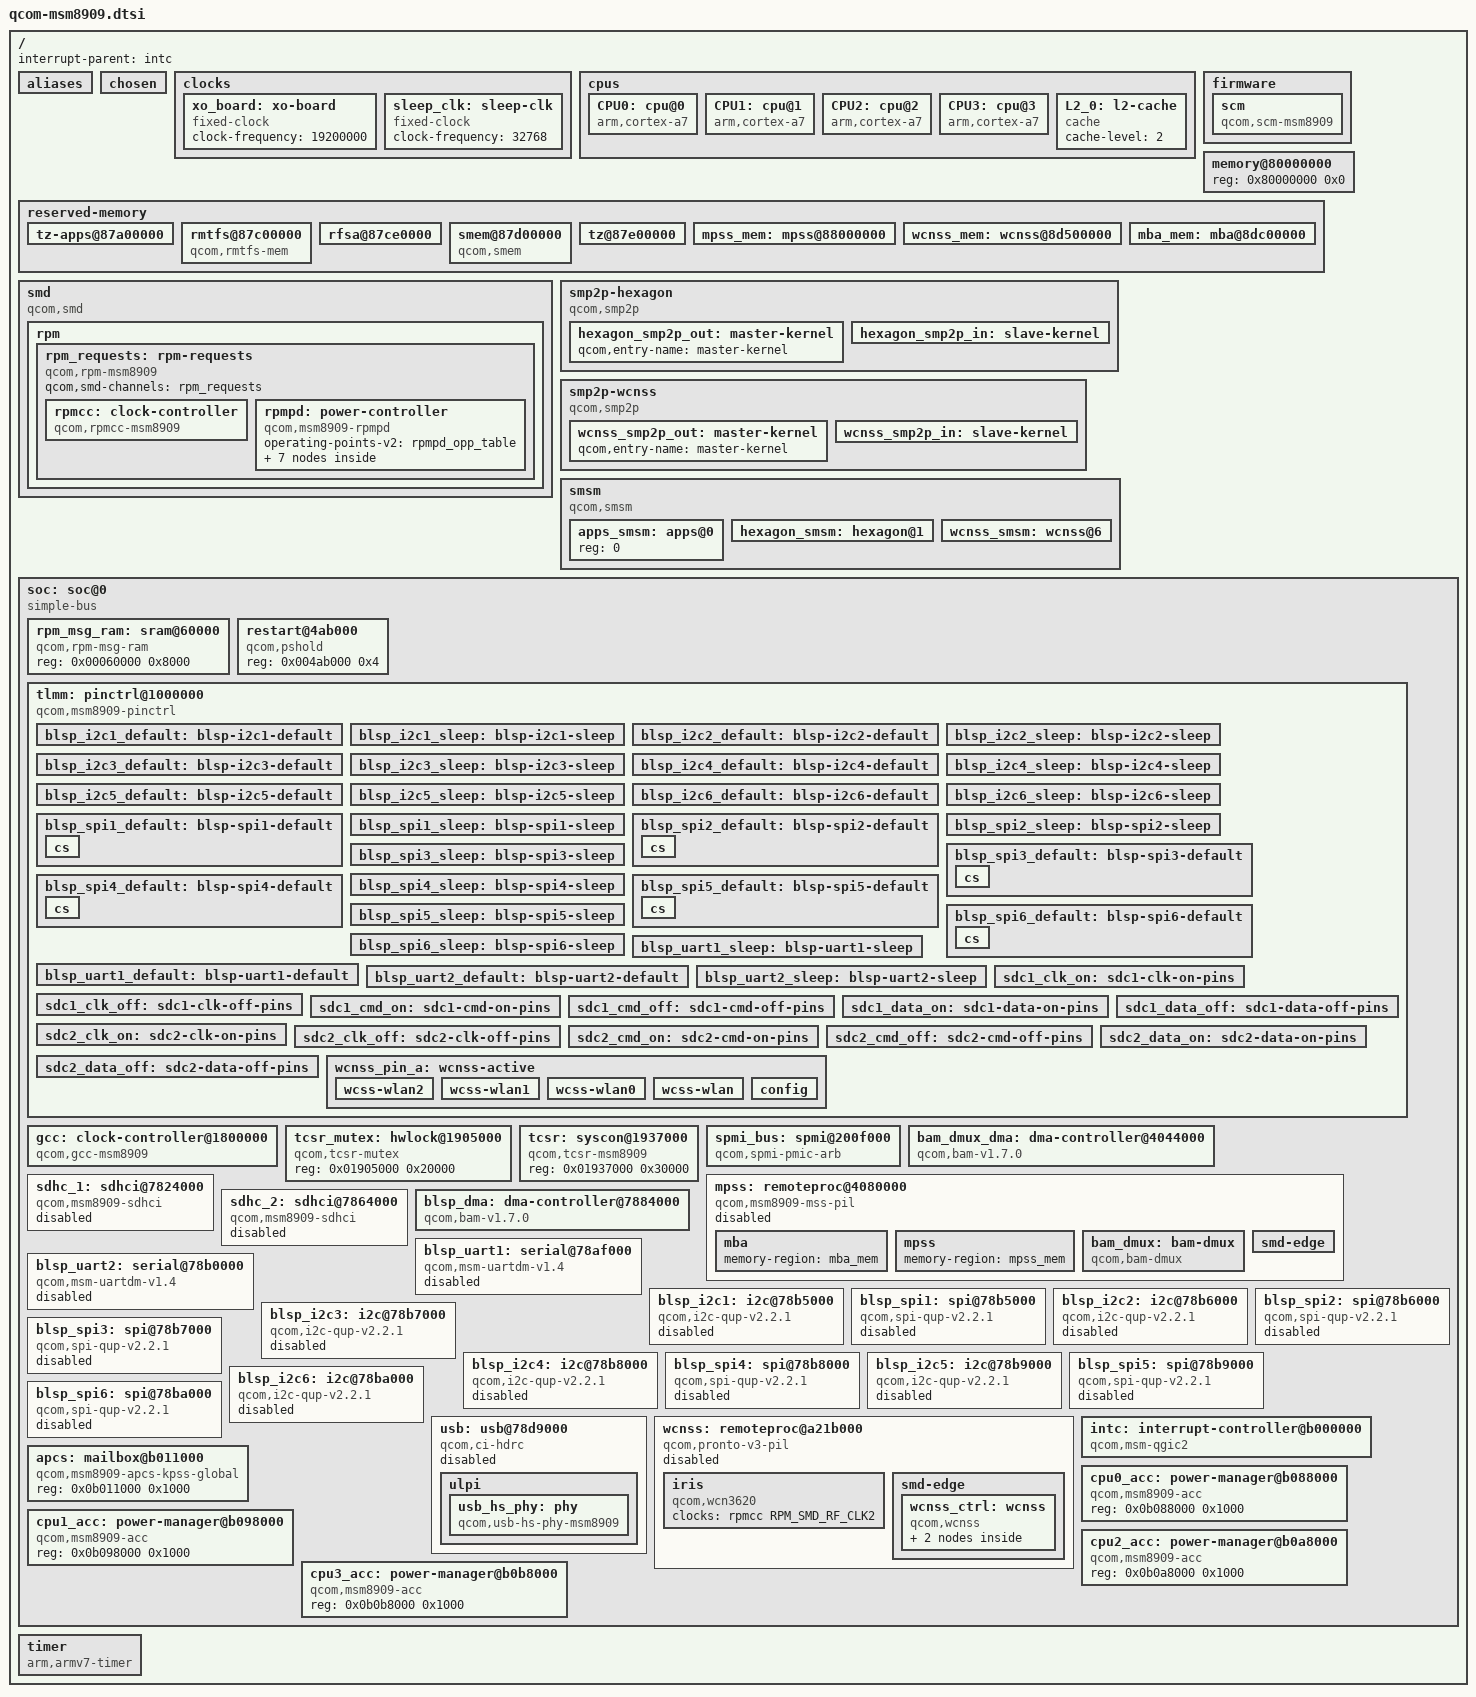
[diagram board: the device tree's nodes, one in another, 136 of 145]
// SPDX-License-Identifier: GPL-2.0-only
/*
 * Copyright (c) 2014-2019, The Linux Foundation. All rights reserved.
 */
/dts-v1/;

#include <dt-bindings/clock/qcom,gcc-msm8909.h>
#include <dt-bindings/clock/qcom,rpmcc.h>
#include <dt-bindings/gpio/gpio.h>
#include <dt-bindings/interrupt-controller/arm-gic.h>
#include <dt-bindings/power/qcom-rpmpd.h>
#include <dt-bindings/reset/qcom,gcc-msm8909.h>

/ {
	#address-cells = <1>;
	#size-cells = <1>;
	interrupt-parent = <&intc>;

	aliases {
		mmc0 = &sdhc_1; /* SDC1 eMMC slot */
		mmc1 = &sdhc_2; /* SDC2 SD card slot */
	};

	chosen { };

	clocks {
		xo_board: xo-board {
			compatible = "fixed-clock";
			#clock-cells = <0>;
			clock-frequency = <19200000>;
		};

		sleep_clk: sleep-clk {
			compatible = "fixed-clock";
			#clock-cells = <0>;
			clock-frequency = <32768>;
		};
	};

	cpus {
		#address-cells = <1>;
		#size-cells = <0>;

		CPU0: cpu@0 {
			device_type = "cpu";
			compatible = "arm,cortex-a7";
			reg = <0x0>;
			next-level-cache = <&L2_0>;
			enable-method = "qcom,msm8909-smp";
			qcom,acc = <&cpu0_acc>;
		};

		CPU1: cpu@1 {
			device_type = "cpu";
			compatible = "arm,cortex-a7";
			reg = <0x1>;
			next-level-cache = <&L2_0>;
			enable-method = "qcom,msm8909-smp";
			qcom,acc = <&cpu1_acc>;
		};

		CPU2: cpu@2 {
			device_type = "cpu";
			compatible = "arm,cortex-a7";
			reg = <0x2>;
			next-level-cache = <&L2_0>;
			enable-method = "qcom,msm8909-smp";
			qcom,acc = <&cpu2_acc>;
		};

		CPU3: cpu@3 {
			device_type = "cpu";
			compatible = "arm,cortex-a7";
			reg = <0x3>;
			next-level-cache = <&L2_0>;
			enable-method = "qcom,msm8909-smp";
			qcom,acc = <&cpu3_acc>;
		};

		L2_0: l2-cache {
			compatible = "cache";
			cache-level = <2>;
		};
	};

	firmware {
		scm: scm {
			compatible = "qcom,scm-msm8909", "qcom,scm";
			clocks = <&gcc GCC_CRYPTO_CLK>,
				 <&gcc GCC_CRYPTO_AXI_CLK>,
				 <&gcc GCC_CRYPTO_AHB_CLK>;
			clock-names = "core", "bus", "iface";
		};
	};

	memory@80000000 {
		device_type = "memory";
		/* We expect the bootloader to fill in the reg */
		reg = <0x80000000 0x0>;
	};

	reserved-memory {
		#address-cells = <1>;
		#size-cells = <1>;
		ranges;

		tz-apps@87a00000 {
			reg = <0x87a00000 0x200000>;
			no-map;
		};
		rmtfs@87c00000 {
			compatible = "qcom,rmtfs-mem";
			reg = <0x87c00000 0xe0000>;
			no-map;

			qcom,client-id = <1>;
		};
		rfsa@87ce0000 {
			reg = <0x87ce0000 0x20000>;
			no-map;
		};
		smem@87d00000 {
			compatible = "qcom,smem";
			reg = <0x87d00000 0x100000>;
			no-map;

			hwlocks = <&tcsr_mutex 3>;
			qcom,rpm-msg-ram = <&rpm_msg_ram>;
		};
		tz@87e00000 {
			reg = <0x87e00000 0x200000>;
			no-map;
		};

		mpss_mem: mpss@88000000 {
			reg = <0x88000000 0x05500000>;
			no-map;
		};
		wcnss_mem: wcnss@8d500000 {
			reg = <0x8d500000 0x700000>;
			no-map;
		};
		mba_mem: mba@8dc00000 {
			reg = <0x8dc00000 0x100000>;
			no-map;
		};
	};

	smd {
		compatible = "qcom,smd";

		rpm {
			interrupts = <GIC_SPI 168 IRQ_TYPE_EDGE_RISING>;
			qcom,ipc = <&apcs 8 0>;
			qcom,smd-edge = <15>;

			rpm_requests: rpm-requests {
				compatible = "qcom,rpm-msm8909";
				qcom,smd-channels = "rpm_requests";

				rpmcc: clock-controller {
					compatible = "qcom,rpmcc-msm8909";
					#clock-cells = <1>;
				};

				rpmpd: power-controller {
					compatible = "qcom,msm8909-rpmpd";
					#power-domain-cells = <1>;
					operating-points-v2 = <&rpmpd_opp_table>;

					rpmpd_opp_table: opp-table {
						compatible = "operating-points-v2";

						rpmpd_opp_ret: opp1 {
							opp-level = <1>;
						};
						rpmpd_opp_svs_krait: opp2 {
							opp-level = <2>;
						};
						rpmpd_opp_svs_soc: opp3 {
							opp-level = <3>;
						};
						rpmpd_opp_nom: opp4 {
							opp-level = <4>;
						};
						rpmpd_opp_turbo: opp5 {
							opp-level = <5>;
						};
						rpmpd_opp_super_turbo: opp6 {
							opp-level = <6>;
						};
					};
				};
			};
		};
	};

	smp2p-hexagon {
		compatible = "qcom,smp2p";
		qcom,smem = <435>, <428>;

		interrupts = <GIC_SPI 27 IRQ_TYPE_EDGE_RISING>;

		qcom,ipc = <&apcs 8 14>;

		qcom,local-pid = <0>;
		qcom,remote-pid = <1>;

		hexagon_smp2p_out: master-kernel {
			qcom,entry-name = "master-kernel";

			#qcom,smem-state-cells = <1>;
		};

		hexagon_smp2p_in: slave-kernel {
			qcom,entry-name = "slave-kernel";

			interrupt-controller;
			#interrupt-cells = <2>;
		};
	};

	smp2p-wcnss {
		compatible = "qcom,smp2p";
		qcom,smem = <451>, <431>;

		interrupts = <GIC_SPI 143 IRQ_TYPE_EDGE_RISING>;

		qcom,ipc = <&apcs 8 18>;

		qcom,local-pid = <0>;
		qcom,remote-pid = <4>;

		wcnss_smp2p_out: master-kernel {
			qcom,entry-name = "master-kernel";

			#qcom,smem-state-cells = <1>;
		};

		wcnss_smp2p_in: slave-kernel {
			qcom,entry-name = "slave-kernel";

			interrupt-controller;
			#interrupt-cells = <2>;
		};
	};

	smsm {
		compatible = "qcom,smsm";

		#address-cells = <1>;
		#size-cells = <0>;

		qcom,ipc-1 = <&apcs 8 13>;
		qcom,ipc-3 = <&apcs 8 19>;

		apps_smsm: apps@0 {
			reg = <0>;

			#qcom,smem-state-cells = <1>;
		};

		hexagon_smsm: hexagon@1 {
			reg = <1>;
			interrupts = <GIC_SPI 26 IRQ_TYPE_EDGE_RISING>;

			interrupt-controller;
			#interrupt-cells = <2>;
		};

		wcnss_smsm: wcnss@6 {
			reg = <6>;
			interrupts = <GIC_SPI 144 IRQ_TYPE_EDGE_RISING>;

			interrupt-controller;
			#interrupt-cells = <2>;
		};
	};

	soc: soc@0 {
		compatible = "simple-bus";
		#address-cells = <1>;
		#size-cells = <1>;
		ranges;

		rpm_msg_ram: sram@60000 {
			compatible = "qcom,rpm-msg-ram";
			reg = <0x00060000 0x8000>;
		};

		restart@4ab000 {
			compatible = "qcom,pshold";
			reg = <0x004ab000 0x4>;
		};

		tlmm: pinctrl@1000000 {
			compatible = "qcom,msm8909-pinctrl";
			reg = <0x01000000 0x300000>;
			interrupts = <GIC_SPI 208 IRQ_TYPE_LEVEL_HIGH>;
			gpio-controller;
			#gpio-cells = <2>;
			gpio-ranges = <&tlmm 0 0 117>;
			interrupt-controller;
			#interrupt-cells = <2>;

			blsp_i2c1_default: blsp-i2c1-default {
				pins = "gpio6", "gpio7";
				function = "blsp_i2c1";

				drive-strength = <2>;
				bias-disable;
			};

			blsp_i2c1_sleep: blsp-i2c1-sleep {
				pins = "gpio6", "gpio7";
				function = "gpio";

				drive-strength = <2>;
				bias-disable;
			};

			blsp_i2c2_default: blsp-i2c2-default {
				pins = "gpio111", "gpio112";
				function = "blsp_i2c2";

				drive-strength = <2>;
				bias-disable;
			};

			blsp_i2c2_sleep: blsp-i2c2-sleep {
				pins = "gpio111", "gpio112";
				function = "gpio";

				drive-strength = <2>;
				bias-disable;
			};

			blsp_i2c3_default: blsp-i2c3-default {
				pins = "gpio29", "gpio30";
				function = "blsp_i2c3";

				drive-strength = <2>;
				bias-disable;
			};

			blsp_i2c3_sleep: blsp-i2c3-sleep {
				pins = "gpio29", "gpio30";
				function = "gpio";

				drive-strength = <2>;
				bias-disable;
			};

			blsp_i2c4_default: blsp-i2c4-default {
				pins = "gpio14", "gpio15";
				function = "blsp_i2c4";

				drive-strength = <2>;
				bias-disable;
			};

			blsp_i2c4_sleep: blsp-i2c4-sleep {
				pins = "gpio14", "gpio15";
				function = "gpio";

				drive-strength = <2>;
				bias-disable;
			};

			blsp_i2c5_default: blsp-i2c5-default {
				pins = "gpio18", "gpio19";
				function = "blsp_i2c5";

				drive-strength = <2>;
				bias-disable;
			};

			blsp_i2c5_sleep: blsp-i2c5-sleep {
				pins = "gpio18", "gpio19";
				function = "gpio";

				drive-strength = <2>;
				bias-disable;
			};

			blsp_i2c6_default: blsp-i2c6-default {
				pins = "gpio10", "gpio11";
				function = "blsp_i2c6";

				drive-strength = <2>;
				bias-disable;
			};

			blsp_i2c6_sleep: blsp-i2c6-sleep {
				pins = "gpio10", "gpio11";
				function = "gpio";

				drive-strength = <2>;
				bias-disable;
			};

			blsp_spi1_default: blsp-spi1-default {
				pins = "gpio4", "gpio5", "gpio7";
				function = "blsp_spi1";

				drive-strength = <12>;
				bias-disable;

				cs {
					pins = "gpio6";
					function = "gpio";

					drive-strength = <2>;
					bias-disable;
					output-high;
				};
			};

			blsp_spi1_sleep: blsp-spi1-sleep {
				pins = "gpio4", "gpio5", "gpio6", "gpio7";
				function = "gpio";

				drive-strength = <2>;
				bias-pull-down;
			};

			blsp_spi2_default: blsp-spi2-default {
				pins = "gpio20", "gpio21", "gpio112";
				function = "blsp_spi2";

				drive-strength = <12>;
				bias-disable;

				cs {
					pins = "gpio111";
					function = "gpio";

					drive-strength = <2>;
					bias-disable;
					output-high;
				};
			};

			blsp_spi2_sleep: blsp-spi2-sleep {
				pins = "gpio20", "gpio21", "gpio111", "gpio112";
				function = "gpio";

				drive-strength = <2>;
				bias-pull-down;
			};

			blsp_spi3_default: blsp-spi3-default {
				pins = "gpio0", "gpio1", "gpio3";
				function = "blsp_spi3";

				drive-strength = <12>;
				bias-disable;

				cs {
					pins = "gpio2";
					function = "gpio";

					drive-strength = <2>;
					bias-disable;
					output-high;
				};
			};

			blsp_spi3_sleep: blsp-spi3-sleep {
				pins = "gpio0", "gpio1", "gpio2", "gpio3";
				function = "gpio";

				drive-strength = <2>;
				bias-pull-down;
			};

			blsp_spi4_default: blsp-spi4-default {
				pins = "gpio12", "gpio13", "gpio15";
				function = "blsp_spi4";

				drive-strength = <12>;
				bias-disable;

				cs {
					pins = "gpio14";
					function = "gpio";

					drive-strength = <2>;
					bias-disable;
					output-high;
				};
			};

			blsp_spi4_sleep: blsp-spi4-sleep {
				pins = "gpio12", "gpio13", "gpio14", "gpio15";
				function = "gpio";

				drive-strength = <2>;
				bias-pull-down;
			};

			blsp_spi5_default: blsp-spi5-default {
				pins = "gpio16", "gpio17", "gpio19";
				function = "blsp_spi5";

				drive-strength = <12>;
				bias-disable;

				cs {
					pins = "gpio18";
					function = "gpio";

					drive-strength = <2>;
					bias-disable;
					output-high;
				};
			};

			blsp_spi5_sleep: blsp-spi5-sleep {
				pins = "gpio16", "gpio17", "gpio18", "gpio19";
				function = "gpio";

				drive-strength = <2>;
				bias-pull-down;
			};

			blsp_spi6_default: blsp-spi6-default {
				pins = "gpio8", "gpio9", "gpio11";
				function = "blsp_spi6";

				drive-strength = <12>;
				bias-disable;

				cs {
					pins = "gpio10";
					function = "gpio";

					drive-strength = <2>;
					bias-pull-up;
				};
			};

			blsp_spi6_sleep: blsp-spi6-sleep {
				pins = "gpio8", "gpio9", "gpio10", "gpio11";
				function = "gpio";

				drive-strength = <2>;
				bias-pull-down;
			};

			blsp_uart1_default: blsp-uart1-default {
				pins = "gpio4", "gpio5";
				function = "blsp_uart1";

				drive-strength = <2>;
				bias-disable;
			};

			blsp_uart1_sleep: blsp-uart1-sleep {
				pins = "gpio4", "gpio5";
				function = "gpio";

				drive-strength = <2>;
				bias-pull-down;
			};

			blsp_uart2_default: blsp-uart2-default {
				pins = "gpio20", "gpio21";
				function = "blsp_uart2";

				drive-strength = <2>;
				bias-disable;
			};

			blsp_uart2_sleep: blsp-uart2-sleep {
				pins = "gpio20", "gpio21";
				function = "gpio";

				drive-strength = <2>;
				bias-pull-down;
			};

			sdc1_clk_on: sdc1-clk-on-pins {
				pins = "sdc1_clk";
				bias-disable;
				drive-strength = <16>;
			};

			sdc1_clk_off: sdc1-clk-off-pins {
				pins = "sdc1_clk";
				bias-disable;
				drive-strength = <2>;
			};

			sdc1_cmd_on: sdc1-cmd-on-pins {
				pins = "sdc1_cmd";
				bias-disable;
				drive-strength = <10>;
			};

			sdc1_cmd_off: sdc1-cmd-off-pins {
				pins = "sdc1_cmd";
				bias-disable;
				drive-strength = <2>;
			};

			sdc1_data_on: sdc1-data-on-pins {
				pins = "sdc1_data";
				bias-pull-up;
				drive-strength = <10>;
			};

			sdc1_data_off: sdc1-data-off-pins {
				pins = "sdc1_data";
				bias-pull-up;
				drive-strength = <2>;
			};

			sdc2_clk_on: sdc2-clk-on-pins {
				pins = "sdc2_clk";
				drive-strength = <16>;
				bias-disable;
			};

			sdc2_clk_off: sdc2-clk-off-pins {
				pins = "sdc2_clk";
				bias-disable;
				drive-strength = <2>;
			};

			sdc2_cmd_on: sdc2-cmd-on-pins {
				pins = "sdc2_cmd";
				bias-pull-up;
				drive-strength = <10>;
			};

			sdc2_cmd_off: sdc2-cmd-off-pins {
				pins = "sdc2_cmd";
				bias-pull-up;
				drive-strength = <2>;
			};

			sdc2_data_on: sdc2-data-on-pins {
				pins = "sdc2_data";
				bias-pull-up;
				drive-strength = <10>;
			};

			sdc2_data_off: sdc2-data-off-pins {
				pins = "sdc2_data";
				bias-pull-up;
				drive-strength = <2>;
			};

			wcnss_pin_a: wcnss-active {
				wcss-wlan2 {
					pins = "gpio40";
					function = "wcss_wlan2";
				};
				wcss-wlan1 {
					pins = "gpio41";
					function = "wcss_wlan1";
				};
				wcss-wlan0 {
					pins = "gpio42";
					function = "wcss_wlan0";
				};
				wcss-wlan {
					pins = "gpio43", "gpio44";
					function = "wcss_wlan";
				};
				config {
					pins = "gpio40", "gpio41", "gpio42",
					       "gpio43", "gpio44";
					drive-strength = <6>;
					bias-pull-up;
				};
			};
		};

		gcc: clock-controller@1800000 {
			compatible = "qcom,gcc-msm8909";
			reg = <0x01800000 0x80000>;
			#clock-cells = <1>;
			#reset-cells = <1>;
			#power-domain-cells = <1>;
			clocks = <&xo_board>, <&sleep_clk>;
			clock-names = "xo", "sleep_clk";
		};

		tcsr_mutex: hwlock@1905000 {
			compatible = "qcom,tcsr-mutex";
			reg = <0x01905000 0x20000>;
			#hwlock-cells = <1>;
		};

		tcsr: syscon@1937000 {
			compatible = "qcom,tcsr-msm8909", "syscon";
			reg = <0x01937000 0x30000>;
		};

		spmi_bus: spmi@200f000 {
			compatible = "qcom,spmi-pmic-arb";
			reg = <0x0200f000 0x001000>,
			      <0x02400000 0x400000>,
			      <0x02c00000 0x400000>,
			      <0x03800000 0x200000>,
			      <0x0200a000 0x002100>;
			reg-names = "core", "chnls", "obsrvr", "intr", "cnfg";
			interrupt-names = "periph_irq";
			interrupts = <GIC_SPI 190 IRQ_TYPE_LEVEL_HIGH>;
			qcom,ee = <0>;
			qcom,channel = <0>;
			#address-cells = <2>;
			#size-cells = <0>;
			interrupt-controller;
			#interrupt-cells = <4>;
		};

		bam_dmux_dma: dma-controller@4044000 {
			compatible = "qcom,bam-v1.7.0";
			reg = <0x04044000 0x19000>;
			interrupts = <GIC_SPI 29 IRQ_TYPE_LEVEL_HIGH>;
			#dma-cells = <1>;
			qcom,ee = <0>;

			num-channels = <6>;
			qcom,num-ees = <1>;
			qcom,powered-remotely;
		};

		mpss: remoteproc@4080000 {
			compatible = "qcom,msm8909-mss-pil";
			reg = <0x04080000 0x100>,
			      <0x04020000 0x040>;
			reg-names = "qdsp6", "rmb";

			interrupts-extended = <&intc GIC_SPI 24 IRQ_TYPE_EDGE_RISING>,
					      <&hexagon_smp2p_in 0 IRQ_TYPE_EDGE_RISING>,
					      <&hexagon_smp2p_in 1 IRQ_TYPE_EDGE_RISING>,
					      <&hexagon_smp2p_in 2 IRQ_TYPE_EDGE_RISING>,
					      <&hexagon_smp2p_in 3 IRQ_TYPE_EDGE_RISING>;
			interrupt-names = "wdog", "fatal", "ready",
					  "handover", "stop-ack";

			power-domains = <&rpmpd MSM8909_VDDCX>,
					<&rpmpd MSM8909_VDDMX_AO>;
			power-domain-names = "cx", "mx";

			clocks = <&gcc GCC_MSS_CFG_AHB_CLK>,
				 <&gcc GCC_MSS_Q6_BIMC_AXI_CLK>,
				 <&gcc GCC_BOOT_ROM_AHB_CLK>,
				 <&xo_board>;
			clock-names = "iface", "bus", "mem", "xo";

			qcom,smem-states = <&hexagon_smp2p_out 0>;
			qcom,smem-state-names = "stop";

			resets = <&gcc GCC_MSS_RESTART>;
			reset-names = "mss_restart";

			qcom,halt-regs = <&tcsr 0x18000 0x19000 0x1a000>;

			status = "disabled";

			mba {
				memory-region = <&mba_mem>;
			};

			mpss {
				memory-region = <&mpss_mem>;
			};

			bam_dmux: bam-dmux {
				compatible = "qcom,bam-dmux";

				interrupt-parent = <&hexagon_smsm>;
				interrupts = <1 IRQ_TYPE_EDGE_BOTH>, <11 IRQ_TYPE_EDGE_BOTH>;
				interrupt-names = "pc", "pc-ack";

				qcom,smem-states = <&apps_smsm 1>, <&apps_smsm 11>;
				qcom,smem-state-names = "pc", "pc-ack";

				dmas = <&bam_dmux_dma 4>, <&bam_dmux_dma 5>;
				dma-names = "tx", "rx";
			};

			smd-edge {
				interrupts = <GIC_SPI 25 IRQ_TYPE_EDGE_RISING>;

				qcom,smd-edge = <0>;
				qcom,ipc = <&apcs 8 12>;
				qcom,remote-pid = <1>;

				label = "hexagon";
			};
		};

		sdhc_1: sdhci@7824000 {
			compatible = "qcom,msm8909-sdhci", "qcom,sdhci-msm-v4";
			reg = <0x07824900 0x11c>, <0x07824000 0x800>;
			reg-names = "hc_mem", "core_mem";

			interrupts = <GIC_SPI 123 IRQ_TYPE_LEVEL_HIGH>,
				     <GIC_SPI 138 IRQ_TYPE_LEVEL_HIGH>;
			interrupt-names = "hc_irq", "pwr_irq";
			clocks = <&gcc GCC_SDCC1_APPS_CLK>,
				 <&gcc GCC_SDCC1_AHB_CLK>,
				 <&xo_board>;
			clock-names = "core", "iface", "xo";

			pinctrl-names = "default", "sleep";
			pinctrl-0 = <&sdc1_clk_on &sdc1_cmd_on &sdc1_data_on>;
			pinctrl-1 = <&sdc1_clk_off &sdc1_cmd_off &sdc1_data_off>;

			mmc-hs200-1_8v;
			mmc-ddr-1_8v;
			bus-width = <8>;
			non-removable;
			status = "disabled";
		};

		sdhc_2: sdhci@7864000 {
			compatible = "qcom,msm8909-sdhci", "qcom,sdhci-msm-v4";
			reg = <0x07864900 0x11c>, <0x07864000 0x800>;
			reg-names = "hc_mem", "core_mem";

			interrupts = <GIC_SPI 125 IRQ_TYPE_LEVEL_HIGH>,
				     <GIC_SPI 221 IRQ_TYPE_LEVEL_HIGH>;
			interrupt-names = "hc_irq", "pwr_irq";
			clocks = <&gcc GCC_SDCC2_APPS_CLK>,
				 <&gcc GCC_SDCC2_AHB_CLK>,
				 <&xo_board>;
			clock-names = "core", "iface", "xo";

			pinctrl-names = "default", "sleep";
			pinctrl-0 = <&sdc2_clk_on &sdc2_cmd_on &sdc2_data_on>;
			pinctrl-1 = <&sdc2_clk_off &sdc2_cmd_off &sdc2_data_off>;

			bus-width = <4>;
			status = "disabled";
		};

		blsp_dma: dma-controller@7884000 {
			compatible = "qcom,bam-v1.7.0";
			reg = <0x07884000 0x23000>;
			interrupts = <GIC_SPI 238 IRQ_TYPE_LEVEL_HIGH>;
			clocks = <&gcc GCC_BLSP1_AHB_CLK>;
			clock-names = "bam_clk";
			#dma-cells = <1>;
			qcom,ee = <0>;
		};

		blsp_uart1: serial@78af000 {
			compatible = "qcom,msm-uartdm-v1.4", "qcom,msm-uartdm";
			reg = <0x078af000 0x200>;
			interrupts = <GIC_SPI 107 IRQ_TYPE_LEVEL_HIGH>;
			clocks = <&gcc GCC_BLSP1_UART1_APPS_CLK>,
				 <&gcc GCC_BLSP1_AHB_CLK>;
			clock-names = "core", "iface";
			dmas = <&blsp_dma 0>, <&blsp_dma 1>;
			dma-names = "tx", "rx";
			pinctrl-names = "default", "sleep";
			pinctrl-0 = <&blsp_uart1_default>;
			pinctrl-1 = <&blsp_uart1_sleep>;
			status = "disabled";
		};

		blsp_uart2: serial@78b0000 {
			compatible = "qcom,msm-uartdm-v1.4", "qcom,msm-uartdm";
			reg = <0x078b0000 0x200>;
			interrupts = <GIC_SPI 108 IRQ_TYPE_LEVEL_HIGH>;
			clocks = <&gcc GCC_BLSP1_UART2_APPS_CLK>,
				 <&gcc GCC_BLSP1_AHB_CLK>;
			clock-names = "core", "iface";
			dmas = <&blsp_dma 2>, <&blsp_dma 3>;
			dma-names = "tx", "rx";
			pinctrl-names = "default", "sleep";
			pinctrl-0 = <&blsp_uart2_default>;
			pinctrl-1 = <&blsp_uart2_sleep>;
			status = "disabled";
		};

		blsp_i2c1: i2c@78b5000 {
			compatible = "qcom,i2c-qup-v2.2.1";
			reg = <0x078b5000 0x500>;
			interrupts = <GIC_SPI 95 IRQ_TYPE_LEVEL_HIGH>;
			clocks = <&gcc GCC_BLSP1_QUP1_I2C_APPS_CLK>,
				 <&gcc GCC_BLSP1_AHB_CLK>;
			clock-names = "core", "iface";
			pinctrl-names = "default", "sleep";
			pinctrl-0 = <&blsp_i2c1_default>;
			pinctrl-1 = <&blsp_i2c1_sleep>;
			#address-cells = <1>;
			#size-cells = <0>;
			status = "disabled";
		};

		blsp_spi1: spi@78b5000 {
			compatible = "qcom,spi-qup-v2.2.1";
			reg = <0x078b5000 0x500>;
			interrupts = <GIC_SPI 95 IRQ_TYPE_LEVEL_HIGH>;
			clocks = <&gcc GCC_BLSP1_QUP1_SPI_APPS_CLK>,
				 <&gcc GCC_BLSP1_AHB_CLK>;
			clock-names = "core", "iface";
			dmas = <&blsp_dma 4>, <&blsp_dma 5>;
			dma-names = "tx", "rx";
			pinctrl-names = "default", "sleep";
			pinctrl-0 = <&blsp_spi1_default>;
			pinctrl-1 = <&blsp_spi1_sleep>;
			#address-cells = <1>;
			#size-cells = <0>;
			status = "disabled";
		};

		blsp_i2c2: i2c@78b6000 {
			compatible = "qcom,i2c-qup-v2.2.1";
			reg = <0x078b6000 0x500>;
			interrupts = <GIC_SPI 96 IRQ_TYPE_LEVEL_HIGH>;
			clocks = <&gcc GCC_BLSP1_QUP2_I2C_APPS_CLK>,
				 <&gcc GCC_BLSP1_AHB_CLK>;
			clock-names = "core", "iface";
			pinctrl-names = "default", "sleep";
			pinctrl-0 = <&blsp_i2c2_default>;
			pinctrl-1 = <&blsp_i2c2_sleep>;
			#address-cells = <1>;
			#size-cells = <0>;
			status = "disabled";
		};

		blsp_spi2: spi@78b6000 {
			compatible = "qcom,spi-qup-v2.2.1";
			reg = <0x078b6000 0x500>;
			interrupts = <GIC_SPI 96 IRQ_TYPE_LEVEL_HIGH>;
			clocks = <&gcc GCC_BLSP1_QUP2_SPI_APPS_CLK>,
				 <&gcc GCC_BLSP1_AHB_CLK>;
			clock-names = "core", "iface";
			dmas = <&blsp_dma 6>, <&blsp_dma 7>;
			dma-names = "tx", "rx";
			pinctrl-names = "default", "sleep";
			pinctrl-0 = <&blsp_spi2_default>;
			pinctrl-1 = <&blsp_spi2_sleep>;
			#address-cells = <1>;
			#size-cells = <0>;
			status = "disabled";
		};

		blsp_i2c3: i2c@78b7000 {
			compatible = "qcom,i2c-qup-v2.2.1";
			reg = <0x078b7000 0x500>;
			interrupts = <GIC_SPI 97 IRQ_TYPE_LEVEL_HIGH>;
			clocks = <&gcc GCC_BLSP1_QUP3_I2C_APPS_CLK>,
				 <&gcc GCC_BLSP1_AHB_CLK>;
			clock-names = "core", "iface";
			pinctrl-names = "default", "sleep";
			pinctrl-0 = <&blsp_i2c3_default>;
			pinctrl-1 = <&blsp_i2c3_sleep>;
			#address-cells = <1>;
			#size-cells = <0>;
			status = "disabled";
		};

		blsp_spi3: spi@78b7000 {
			compatible = "qcom,spi-qup-v2.2.1";
			reg = <0x078b7000 0x500>;
			interrupts = <GIC_SPI 97 IRQ_TYPE_LEVEL_HIGH>;
			clocks = <&gcc GCC_BLSP1_QUP3_SPI_APPS_CLK>,
				 <&gcc GCC_BLSP1_AHB_CLK>;
			clock-names = "core", "iface";
			dmas = <&blsp_dma 8>, <&blsp_dma 9>;
			dma-names = "tx", "rx";
			pinctrl-names = "default", "sleep";
			pinctrl-0 = <&blsp_spi3_default>;
			pinctrl-1 = <&blsp_spi3_sleep>;
			#address-cells = <1>;
			#size-cells = <0>;
			status = "disabled";
		};

		blsp_i2c4: i2c@78b8000 {
			compatible = "qcom,i2c-qup-v2.2.1";
			reg = <0x078b8000 0x500>;
			interrupts = <GIC_SPI 98 IRQ_TYPE_LEVEL_HIGH>;
			clocks = <&gcc GCC_BLSP1_QUP4_I2C_APPS_CLK>,
				 <&gcc GCC_BLSP1_AHB_CLK>;
			clock-names = "core", "iface";
			pinctrl-names = "default", "sleep";
			pinctrl-0 = <&blsp_i2c4_default>;
			pinctrl-1 = <&blsp_i2c4_sleep>;
			#address-cells = <1>;
			#size-cells = <0>;
			status = "disabled";
		};

		blsp_spi4: spi@78b8000 {
			compatible = "qcom,spi-qup-v2.2.1";
			reg = <0x078b8000 0x500>;
			interrupts = <GIC_SPI 98 IRQ_TYPE_LEVEL_HIGH>;
			clocks = <&gcc GCC_BLSP1_QUP4_SPI_APPS_CLK>,
				 <&gcc GCC_BLSP1_AHB_CLK>;
			clock-names = "core", "iface";
			dmas = <&blsp_dma 10>, <&blsp_dma 11>;
			dma-names = "tx", "rx";
			pinctrl-names = "default", "sleep";
			pinctrl-0 = <&blsp_spi4_default>;
			pinctrl-1 = <&blsp_spi4_sleep>;
			#address-cells = <1>;
			#size-cells = <0>;
			status = "disabled";
		};

		blsp_i2c5: i2c@78b9000 {
			compatible = "qcom,i2c-qup-v2.2.1";
			reg = <0x078b9000 0x500>;
			interrupts = <GIC_SPI 99 IRQ_TYPE_LEVEL_HIGH>;
			clocks = <&gcc GCC_BLSP1_QUP5_I2C_APPS_CLK>,
				 <&gcc GCC_BLSP1_AHB_CLK>;
			clock-names = "core", "iface";
			pinctrl-names = "default", "sleep";
			pinctrl-0 = <&blsp_i2c5_default>;
			pinctrl-1 = <&blsp_i2c5_sleep>;
			#address-cells = <1>;
			#size-cells = <0>;
			status = "disabled";
		};

		blsp_spi5: spi@78b9000 {
			compatible = "qcom,spi-qup-v2.2.1";
			reg = <0x078b9000 0x500>;
			interrupts = <GIC_SPI 99 IRQ_TYPE_LEVEL_HIGH>;
			clocks = <&gcc GCC_BLSP1_QUP5_SPI_APPS_CLK>,
				 <&gcc GCC_BLSP1_AHB_CLK>;
			clock-names = "core", "iface";
			dmas = <&blsp_dma 12>, <&blsp_dma 13>;
			dma-names = "tx", "rx";
			pinctrl-names = "default", "sleep";
			pinctrl-0 = <&blsp_spi5_default>;
			pinctrl-1 = <&blsp_spi5_sleep>;
			#address-cells = <1>;
			#size-cells = <0>;
			status = "disabled";
		};

		blsp_i2c6: i2c@78ba000 {
			compatible = "qcom,i2c-qup-v2.2.1";
			reg = <0x078ba000 0x500>;
			interrupts = <GIC_SPI 100 IRQ_TYPE_LEVEL_HIGH>;
			clocks = <&gcc GCC_BLSP1_QUP6_I2C_APPS_CLK>,
				 <&gcc GCC_BLSP1_AHB_CLK>;
			clock-names = "core", "iface";
			pinctrl-names = "default", "sleep";
			pinctrl-0 = <&blsp_i2c6_default>;
			pinctrl-1 = <&blsp_i2c6_sleep>;
			#address-cells = <1>;
			#size-cells = <0>;
			status = "disabled";
		};

		blsp_spi6: spi@78ba000 {
			compatible = "qcom,spi-qup-v2.2.1";
			reg = <0x078ba000 0x500>;
			interrupts = <GIC_SPI 100 IRQ_TYPE_LEVEL_HIGH>;
			clocks = <&gcc GCC_BLSP1_QUP6_SPI_APPS_CLK>,
				 <&gcc GCC_BLSP1_AHB_CLK>;
			clock-names = "core", "iface";
			dmas = <&blsp_dma 14>, <&blsp_dma 15>;
			dma-names = "tx", "rx";
			pinctrl-names = "default", "sleep";
			pinctrl-0 = <&blsp_spi6_default>;
			pinctrl-1 = <&blsp_spi6_sleep>;
			#address-cells = <1>;
			#size-cells = <0>;
			status = "disabled";
		};

		usb: usb@78d9000 {
			compatible = "qcom,ci-hdrc";
			reg = <0x078d9000 0x200>, <0x078d9200 0x200>;
			interrupts = <GIC_SPI 134 IRQ_TYPE_LEVEL_HIGH>,
				     <GIC_SPI 140 IRQ_TYPE_LEVEL_HIGH>;
			clocks = <&gcc GCC_USB_HS_AHB_CLK>,
				 <&gcc GCC_USB_HS_SYSTEM_CLK>;
			clock-names = "iface", "core";
			assigned-clocks = <&gcc GCC_USB_HS_SYSTEM_CLK>;
			assigned-clock-rates = <80000000>;
			resets = <&gcc GCC_USB_HS_BCR>;
			reset-names = "core";
			phy_type = "ulpi";
			dr_mode = "otg";
			hnp-disable;
			srp-disable;
			adp-disable;
			ahb-burst-config = <0>;
			phy-names = "usb-phy";
			phys = <&usb_hs_phy>;
			status = "disabled";
			#reset-cells = <1>;

			ulpi {
				usb_hs_phy: phy {
					compatible = "qcom,usb-hs-phy-msm8909",
						     "qcom,usb-hs-phy";
					#phy-cells = <0>;
					clocks = <&xo_board>, <&gcc GCC_USB2A_PHY_SLEEP_CLK>;
					clock-names = "ref", "sleep";
					resets = <&gcc GCC_USB2_HS_PHY_ONLY_BCR>, <&usb 0>;
					reset-names = "phy", "por";
					qcom,init-seq = /bits/ 8 <0x0 0x73>;
				};
			};
		};

		wcnss: remoteproc@a21b000 {
			compatible = "qcom,pronto-v3-pil", "qcom,pronto";
			reg = <0x0a204000 0x2000>, <0x0a202000 0x1000>, <0x0a21b000 0x3000>;
			reg-names = "ccu", "dxe", "pmu";

			memory-region = <&wcnss_mem>;

			interrupts-extended = <&intc GIC_SPI 149 IRQ_TYPE_EDGE_RISING>,
					      <&wcnss_smp2p_in 0 IRQ_TYPE_EDGE_RISING>,
					      <&wcnss_smp2p_in 1 IRQ_TYPE_EDGE_RISING>,
					      <&wcnss_smp2p_in 2 IRQ_TYPE_EDGE_RISING>,
					      <&wcnss_smp2p_in 3 IRQ_TYPE_EDGE_RISING>;
			interrupt-names = "wdog", "fatal", "ready", "handover", "stop-ack";

			power-domains = <&rpmpd MSM8909_VDDCX>,
					<&rpmpd MSM8909_VDDMX>;
			power-domain-names = "cx", "mx";

			qcom,smem-states = <&wcnss_smp2p_out 0>;
			qcom,smem-state-names = "stop";

			pinctrl-names = "default";
			pinctrl-0 = <&wcnss_pin_a>;

			status = "disabled";

			iris {
				compatible = "qcom,wcn3620";

				clocks = <&rpmcc RPM_SMD_RF_CLK2>;
				clock-names = "xo";
			};

			smd-edge {
				interrupts = <GIC_SPI 142 IRQ_TYPE_EDGE_RISING>;

				qcom,ipc = <&apcs 8 17>;
				qcom,smd-edge = <6>;
				qcom,remote-pid = <4>;

				label = "pronto";

				wcnss_ctrl: wcnss {
					compatible = "qcom,wcnss";
					qcom,smd-channels = "WCNSS_CTRL";

					qcom,mmio = <&wcnss>;

					wcnss_bt: bluetooth {
						compatible = "qcom,wcnss-bt";
					};

					wcnss_wifi: wifi {
						compatible = "qcom,wcnss-wlan";

						interrupts = <GIC_SPI 145 IRQ_TYPE_LEVEL_HIGH>,
							     <GIC_SPI 146 IRQ_TYPE_LEVEL_HIGH>;
						interrupt-names = "tx", "rx";

						qcom,smem-states = <&apps_smsm 10>, <&apps_smsm 9>;
						qcom,smem-state-names = "tx-enable", "tx-rings-empty";
					};
				};
			};
		};

		intc: interrupt-controller@b000000 {
			compatible = "qcom,msm-qgic2";
			reg = <0x0b000000 0x1000>,
			      <0x0b002000 0x1000>;
			interrupt-controller;
			#interrupt-cells = <3>;
		};

		apcs: mailbox@b011000 {
			compatible = "qcom,msm8909-apcs-kpss-global", "syscon";
			reg = <0x0b011000 0x1000>;
			#mbox-cells = <1>;
		};

		cpu0_acc: power-manager@b088000 {
			compatible = "qcom,msm8909-acc";
			reg = <0x0b088000 0x1000>;
		};
		cpu1_acc: power-manager@b098000 {
			compatible = "qcom,msm8909-acc";
			reg = <0x0b098000 0x1000>;
		};
		cpu2_acc: power-manager@b0a8000 {
			compatible = "qcom,msm8909-acc";
			reg = <0x0b0a8000 0x1000>;
		};
		cpu3_acc: power-manager@b0b8000 {
			compatible = "qcom,msm8909-acc";
			reg = <0x0b0b8000 0x1000>;
		};
	};

	timer {
		compatible = "arm,armv7-timer";
		interrupts = <GIC_PPI 2 (GIC_CPU_MASK_SIMPLE(4) | IRQ_TYPE_LEVEL_LOW)>,
			     <GIC_PPI 3 (GIC_CPU_MASK_SIMPLE(4) | IRQ_TYPE_LEVEL_LOW)>,
			     <GIC_PPI 4 (GIC_CPU_MASK_SIMPLE(4) | IRQ_TYPE_LEVEL_LOW)>,
			     <GIC_PPI 1 (GIC_CPU_MASK_SIMPLE(4) | IRQ_TYPE_LEVEL_LOW)>;
	};
};
